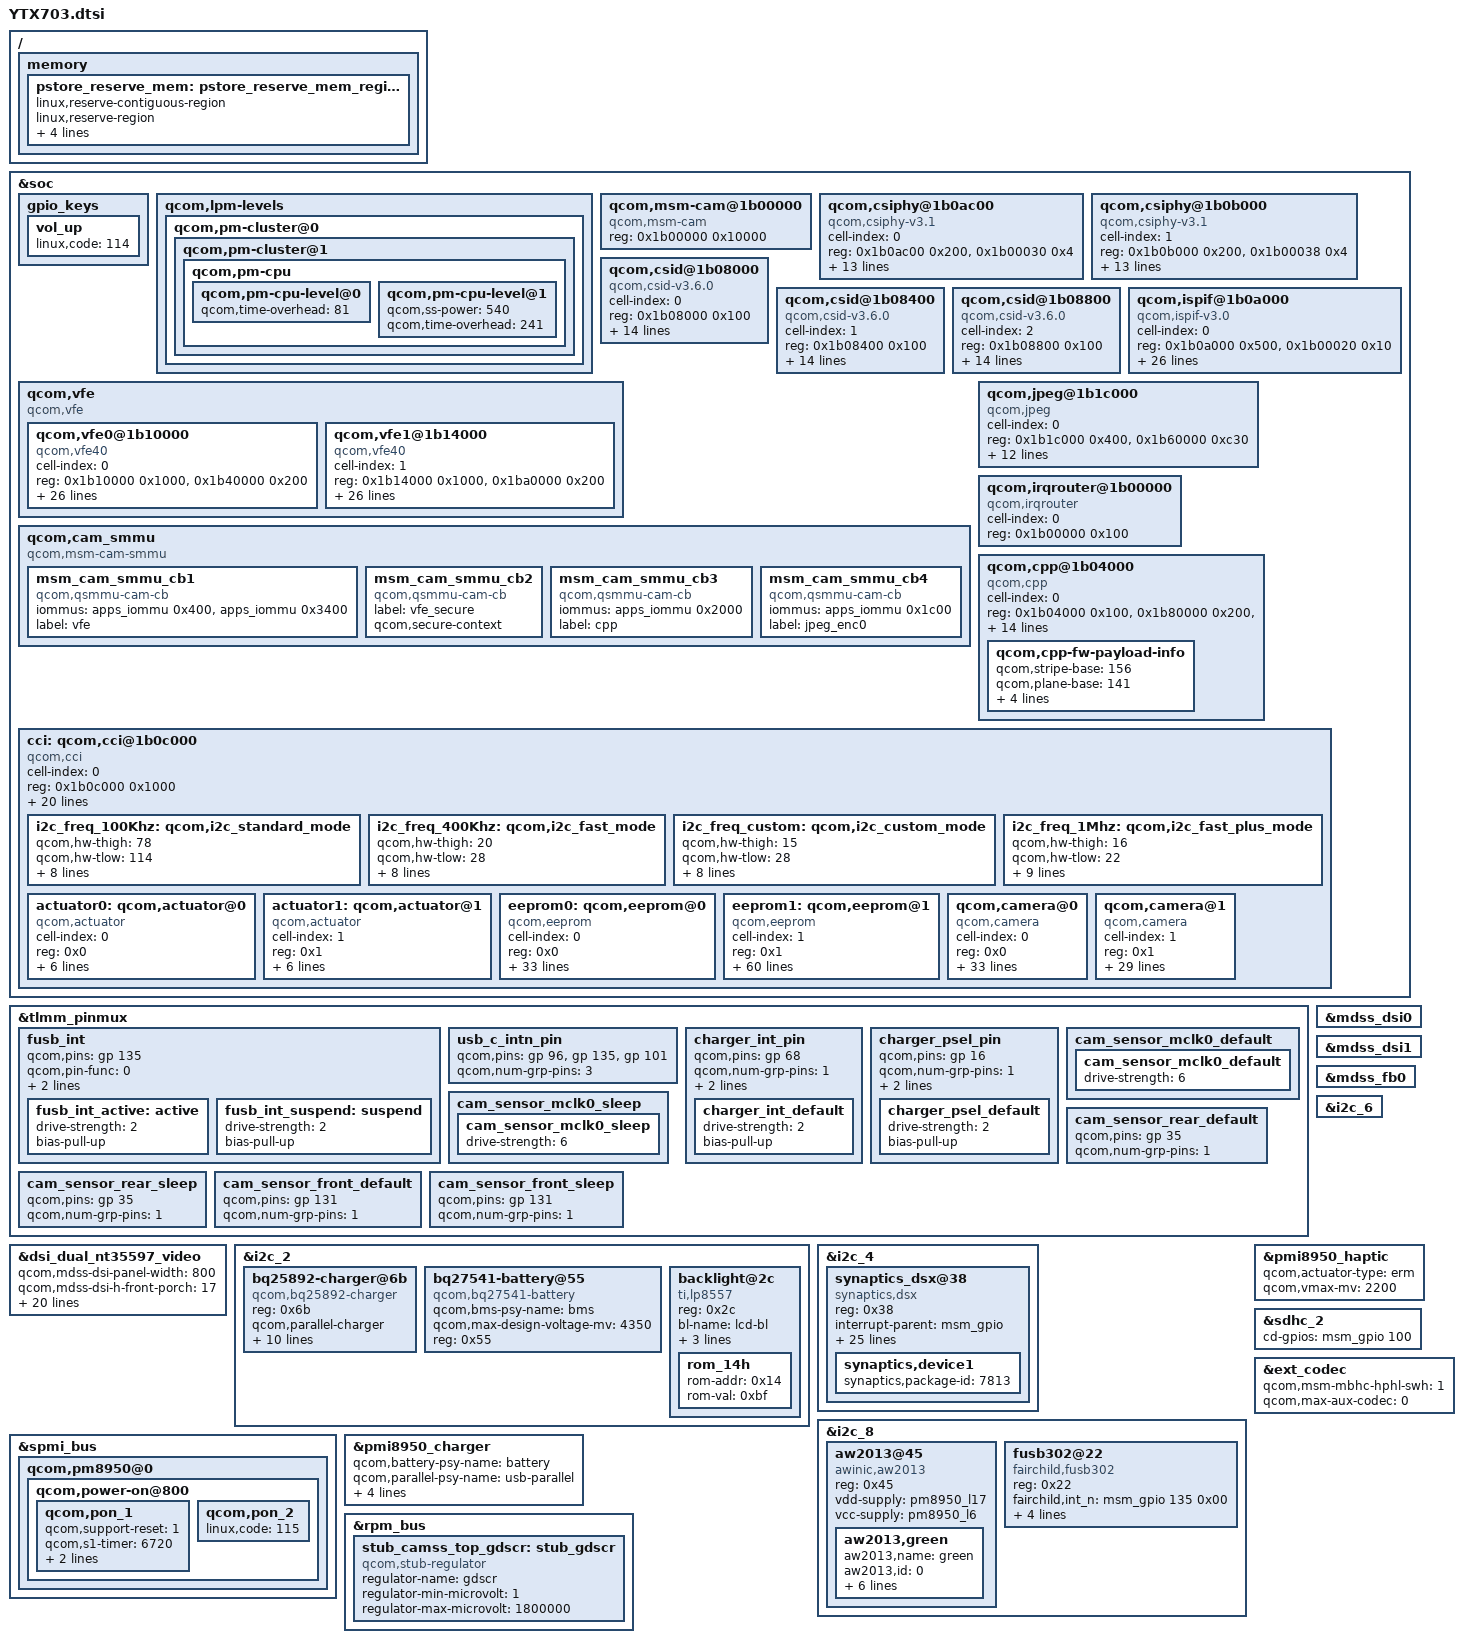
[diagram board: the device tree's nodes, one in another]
/*
 * Copyright (C) 2018 The LineageOS Project
 *
 * This program is free software; you can redistribute it and/or modify
 * it under the terms of the GNU General Public License version 2 and
 * only version 2 as published by the Free Software Foundation.
 *
 * This program is distributed in the hope that it will be useful,
 * but WITHOUT ANY WARRANTY; without even the implied warranty of
 * MERCHANTABILITY or FITNESS FOR A PARTICULAR PURPOSE.  See the
 * GNU General Public License for more details.
 */

/ {
	/* pstore: reserved DDR memory region for post-mortem kernel logs */
	memory {
		pstore_reserve_mem: pstore_reserve_mem_region@0 {
			linux,reserve-contiguous-region;
			linux,reserve-region;
			linux,remove-completely;
			reg = <0x00000000 0x30000000    /* Address */
			       0x00000000 0x00300000>;  /* Size */
			label = "pstore_reserve_mem";
		};
	};
};

&soc {
	/* Compensate for hardware-reversed VOL-UP and VOL-DOWN buttons */
	gpio_keys {
		vol_up {
			linux,code = <114>; /* KEY_VOLUMEDOWN */
		};
	};
	/*
	 * Documentation/devicetree/bindings/arm/msm/lpm-levels.txt
	 * Overrides msm8976-pm.dtsi
	 */
	qcom,lpm-levels {
		qcom,pm-cluster@0 {
			qcom,pm-cluster@1{
				qcom,pm-cpu {
					qcom,pm-cpu-level@0 {
						qcom,time-overhead = <81>;  /* Was 61 */
					};
					qcom,pm-cpu-level@1 {
						qcom,ss-power      = <540>; /* Was 545 */
						qcom,time-overhead = <241>; /* Was 239 */
					};
				};
			};
		};
	};
};

/*
 * Pin muxing settings
 * Overrides msm8976-pinctrl.dtsi
 */
&tlmm_pinmux {
	fusb_int {
		qcom,pins = <&gp 135>;
		qcom,pin-func = <0>;
		qcom,num-grp-pins = <1>;
		label = "fusb_int";
		fusb_int_active: active {
			drive-strength = <2>; /* mA */
			bias-pull-up;
		};
		fusb_int_suspend: suspend {
			drive-strength = <2>; /* mA */
			bias-pull-up;
		};
	};
	usb_c_intn_pin {
		qcom,pins = <&gp 96>, <&gp 135>, <&gp 101>;
		qcom,num-grp-pins = <3>;
	};
	charger_int_pin {
		qcom,pins = <&gp 68>;
		qcom,num-grp-pins = <1>;
		qcom,pin-func = <1>;
		label = "charger_int_pin";
		charger_int_default: charger_int_default {
			drive-strength = <2>; /* mA */
			bias-pull-up;
		};
	};
	charger_psel_pin {
		qcom,pins = <&gp 16>;
		qcom,num-grp-pins = <1>;
		qcom,pin-func = <0>;
		label = "charger_psel_pin";
		charger_psel_default:  charger_psel_default {
			drive-strength = <2>; /* mA */
			bias-pull-up;
		};
	};
	cam_sensor_mclk0_default {
		cam_sensor_mclk0_default {
			drive-strength = <6>; /* mA, previously 2 */
		};
	};
	cam_sensor_mclk0_sleep {
		cam_sensor_mclk0_sleep {
			drive-strength = <6>; /* mA, previously 2 */
		};
	};
	cam_sensor_rear_default {
		qcom,pins = <&gp 35>; /* STANDBY - RESET pin is removed */
		qcom,num-grp-pins = <1>;
	};
	cam_sensor_rear_sleep {
		qcom,pins = <&gp 35>; /* STANDBY - RESET pin is removed */
		qcom,num-grp-pins = <1>;
	};
	cam_sensor_front_default {
		qcom,pins = <&gp 131>; /* RESET - STANDBY pin is removed */
		qcom,num-grp-pins = <1>;
	};
	cam_sensor_front_sleep {
		qcom,pins = <&gp 131>; /* RESET - STANDBY pin is removed */
		qcom,num-grp-pins = <1>;
	};
};

/* LCD panel
 * - Documentation/devicetree/bindings/fb/mdss-dsi-panel.txt
 * - Overrides dsi-panel-nt35597-dualmipi-wqxga-video.dtsi
 */
&dsi_dual_nt35597_video {
	qcom,mdss-dsi-panel-width = <800>;  /* Previously 720 */
	qcom,mdss-dsi-h-front-porch = <17>; /* Horizontal front porch in pixels; previously 100 */
	qcom,mdss-dsi-h-back-porch = <30>;  /* Horizontal back porch in pixels; previously 32 */
	qcom,mdss-dsi-h-pulse-width = <4>;  /* Previously 16 */
	qcom,mdss-dsi-v-back-porch = <24>;  /* Vertical back porch in pixels; previously 7 */
	qcom,mdss-dsi-v-front-porch = <16>; /* Vertical front porch in pixels; previously 8 */
	qcom,mdss-dsi-v-pulse-width = <8>;  /* Previously 1 */
	qcom,mdss-dsi-bl-pmic-control-type = "bl_ctrl_dcs"; /* control backlight via dsi commands */
	/* Backlight controller operates in range 0<x<256 */
	qcom,mdss-dsi-bl-min-level = <0x01>;
	qcom,mdss-dsi-bl-max-level = <0xFF>;
	qcom,mdss-dsi-on-command =
	       [39 01 00 00 01 00 06 f0 55 aa 52 08 00 /* Set internal registers */
	        15 01 00 00 01 00 02 c0 0d
	        39 01 00 00 01 00 05 b8 03 06 00 00
	        39 01 00 00 01 00 05 ff aa 55 a5 80 /* Set internal registers */
	        15 01 00 00 01 00 02 6f 0f
	        15 01 00 00 01 00 02 f7 01
	        39 01 00 00 01 00 05 ff aa 55 a5 00 /* Set internal registers */
	        15 01 00 00 01 00 02 62 01
	        15 01 00 00 01 00 02 51 80 /* Set initial brightness set to 0x80 */
	        05 01 00 00 78 00 02 11 00 /* Exit the sleep mode */
	       ];
	/* DSI PHY timings */
	qcom,mdss-dsi-panel-timings = [D5 32 22 00 60 64 26 34 29 03 04 00];
	qcom,mdss-dsi-post-panel-on-command =
	       [39 01 00 00 01 00 02 FF 23 /* Enter CMD2 page3 */
	        39 01 00 00 00 00 02 00 02 /* DMCT = 1, Select the enable / disable mechanism for CABC and Manual dimming functions. */
	        39 01 00 00 00 00 02 05 24 /* Moving mode dimming 32step, still mode 32step */
	        39 01 00 00 00 00 02 FB 01 /* MTP do not reload CMD2 P3 */
	        39 01 00 00 01 00 02 FF 10 /* Enter CMD1 */
	        15 01 00 00 01 00 02 53 2C /* Enable backlight via pwm control.
	                                      Enable dimming in general (with or w/o cabc). */
	        05 01 00 00 15 00 02 29 00 /* Display on */
	      ];

	/* CABC init commands / values */
	cm,mdss-livedisplay-cabc-cmd = [
	    15 01 00 00 01 00 02 55 00 /* CABC (0: off, 1: UI, 2: Picture, 3: Video) */
	];
	cm,mdss-livedisplay-cabc-ui-value = <0x02>;
	cm,mdss-livedisplay-cabc-image-value = <0x02>;
	cm,mdss-livedisplay-cabc-video-value = <0x02>;
};
/*
 * Overrides msm8976-mdss-mtp.dtsi
 */
&dsi_dual_nt35597_video {
	/delete-property/ qcom,mdss-dsi-pan-enable-dynamic-fps;
	/delete-property/ qcom,mdss-dsi-pan-fps-update;
};
&mdss_dsi0 {
	/delete-property/ qcom,platform-bklight-en-gpio;
};
&mdss_dsi1 {
	/delete-property/ qcom,platform-bklight-en-gpio;
};
/*
 * Disable Linux splash screen at boot
 * Overrides msm8976-mdss.dtsi
 */
&mdss_fb0 {
	/delete-property/ qcom,mdss-fb-splash-logo-enabled;
};

/*
 * Bindings for I2C peripherals
 * Overrides msm8976-mtp.dtsi
 */
&i2c_2 {
	/delete-node/ smb1351-charger@1d;
	bq25892-charger@6b {
		compatible = "qcom,bq25892-charger";
		reg = <0x6b>;
		qcom,parallel-charger;
		qcom,parallel-psy-name = "usb-parallel";
		qcom,float-voltage-mv = <4352>;
		qcom,recharge-mv = <200>;
		qcom,fastchg-current-max-ma = <3800>;
		qcom,iterm-ma = <192>;
		interrupt-parent = <&msm_gpio>;
		interrupts = <68 0>;
		pinctrl-names = "default";
		pinctrl-0 = <&charger_int_default &charger_psel_default>;
		qcom,psel-gpio = <&msm_gpio 16 0>;
	};
	bq27541-battery@55 {
		compatible = "qcom,bq27541-battery";
		qcom,bms-psy-name = "bms";
		qcom,max-design-voltage-mv = <4350>;
		reg = <0x55>;
	};
	backlight@2c {
		compatible = "ti,lp8557";
		reg = <0x2c>;
		bl-name = "lcd-bl";
		dev-ctrl = /bits/ 8 <0x07>; /* see lp8557 documentation, unshaped PWM × brigthness register mode */
		init-brt = /bits/ 8 <0xFF>; /* 255 as initial brightness value;
					       will be multiplied with the value provided by display pwm */
		/* Full-scale LED current (I_LED):
		 * 0:  5 mA,  1: 10 mA,  2: 13 mA,  3: 15 mA,
		 * 4: 18 mA,  5: 20 mA,  6: 23 mA,  7: 25 mA
		 */
		maxcurr-led = <7>;
		/* 4V OV, 4 output LED string enabled */
		rom_14h {
			rom-addr = /bits/ 8 <0x14>;
			rom-val = /bits/ 8 <0xbf>;
		};
	};
};
&i2c_4 {
	/delete-node/ synaptics@20;
	synaptics_dsx@38 {
		compatible = "synaptics,dsx";
		reg = <0x38>;
		interrupt-parent = <&msm_gpio>;
		interrupts = <65 0x2008>;
		avdd-supply = <&pm8950_l17>;
		vdd-supply = <&pm8950_l6>;
		synaptics,pwr-reg-name = "vdd_ana";
		synaptics,bus-reg-name = "vcc_i2c";
		clock-names = "iface_clk", "core_clk";
		clocks = <&clock_gcc clk_gcc_blsp1_ahb_clk>,
			<&clock_gcc clk_gcc_blsp1_qup4_i2c_apps_clk>;
		/* pins used by touchscreen */
		pinctrl-names = "pmx_ts_active","pmx_ts_suspend","pmx_ts_release";
		pinctrl-0 = <&ts_int_active &ts_reset_active>;
		pinctrl-1 = <&ts_int_suspend &ts_reset_suspend>;
		pinctrl-2 = <&ts_release>;
		synaptics,irq-gpio = <&msm_gpio 65 0x2008>;
		synaptics,reset-gpio = <&msm_gpio 64 0x0>;
		synaptics,i2c-pull-up;
		synaptics,power-down;
		synaptics,disable-gpios;
		synaptics,detect-device;
		synaptics,bypass-packrat-id-check;
		synaptics,power-delay-ms = <60>;
		synaptics,reset-on-state = <0>;
		synaptics,reset-active-ms = <10>;
		synaptics,reset-delay-ms = <60>;
		synaptics,ub-i2c-addr = <0x20>;
		synaptics,irq-flags = <0x2008>; /* IRQF_ONESHOT | IRQF_TRIGGER_LOW */
		synaptics,swap-axes; /* ro.sf.hwrotation=90 */
		synaptics,y-flip;
		synaptics,device1 {
			synaptics,package-id = <7813>;
		};
	};
};
&i2c_6 {
	/delete-node/ nq@2b;
};
&i2c_8 {
	aw2013@45 {
		compatible = "awinic,aw2013";
		reg = <0x45>;
		vdd-supply = <&pm8950_l17>; /* msm8976-regulator.dtsi */
		vcc-supply = <&pm8950_l6>;
		aw2013,green {
			aw2013,name = "green";
			aw2013,id = <0>;
			aw2013,max-brightness = <255>;
			aw2013,max-current = <1>;
			aw2013,rise-time-ms = <2>;
			aw2013,hold-time-ms = <1>;
			aw2013,fall-time-ms = <2>;
			aw2013,off-time-ms  = <1>;
		};
	};
	fusb302@22 {
		compatible = "fairchild,fusb302";
		reg = <0x22>;
		fairchild,int_n = <&msm_gpio 135 0x00>;
		interrupt-parent = <&msm_gpio>;
		interrupts = <135 0>; /* MSM GPIO 102 */
		interrupt-names = "fsc_interrupt_int_n";
		pinctrl-names = "fusb_active", "fusb_suspend";
		pinctrl-0 = <&fusb_int_active>;
		pinctrl-1 = <&fusb_int_suspend>;
	};
};

/* SPMI bus peripherals */
&spmi_bus {
	/*
	 * Overrides msm-pm8950.dtsi
	 */
	qcom,pm8950@0 {
		qcom,power-on@800 {
			/* Power button */
			qcom,pon_1 {
				qcom,support-reset = <1>;
				qcom,s1-timer = <6720>; /* button delay until poweroff */
				qcom,s2-timer = <2000>; /* button delay until reboot */
				qcom,s2-type = <5>;
			};
			/* Compensate for hardware-reversed VOL-UP and VOL-DOWN buttons */
			qcom,pon_2 {
				linux,code = <115>; /* KEY_VOLUMEUP */
			};
		};
	};
};
/*
 * Vibration motor
 * Overrides:
 * - msm-pmi8950.dtsi
 * - msm8976-mtp.dtsi
 */
&pmi8950_haptic {
	qcom,actuator-type = "erm";
	qcom,vmax-mv = <2200>;
};
/*
 * Charger
 * Overrides msm-pmi8950.dtsi
 */
&pmi8950_charger { /* qcom,qpnp-smbcharger */
	qcom,battery-psy-name   = "battery";      /* smbcharger driver will register this */
	qcom,parallel-psy-name  = "usb-parallel"; /* BQ25892 */
	qcom,bms-psy-name       = "bms";          /* BQ27541 fuel gauge meter */
	qcom,usb-psy-name       = "usb";          /* phy-msm-usb */
	qcom,fastchg-current-ma = <3000>;
	qcom,iterm-disabled;
	/delete-property/ qcom,iterm-ma;
	/delete-property/ qcom,float-voltage-mv;  /* Moved to BQ25892 */
	/delete-property/ qcom,resume-delta-mv;
	/delete-property/ qcom,autoadjust-vfloat;
	/delete-property/ qcom,force-aicl-rerun;
	/delete-property/ qcom,aicl-rerun-period-s;
	/delete-property/ qcom,charging-disabled;
};

/* SDHC controller
 * - Overrides msm8976-mtp.dtsi
 * - Documentation/devicetree/bindings/mmc/sdhci-msm.txt
 */
&sdhc_2 { /* SDC2 SD card slot */
	/* Disable OF_GPIO_ACTIVE_LOW by default.
	 * Setting will be overridden by drivers/mmc/host/sdhci-msm.c
	 * if bootloader sets com_board_ver < 3 in cmdline.
	 */
	cd-gpios = <&msm_gpio 100 0x0>;
};

/*
 * Audio settings
 * - Overrides msm8976.dtsi
 * - Documentation/devicetree/bindings/sound/qcom-audio-dev.txt
 */
&ext_codec {
	qcom,msm-mbhc-hphl-swh = <1>; /* Headset detection switch is normally open */
	qcom,max-aux-codec = <0>; /* Don't use any wsa881x audio codec */
};

/*
 * RPM bus
 * Overrides msm8976-regulator.dtsi
 * Documentation/devicetree/bindings/regulator/stub-regulator.txt
 */
&rpm_bus {
	stub_camss_top_gdscr: stub_gdscr {
		compatible = "qcom,stub-regulator";
		regulator-name = "gdscr";
		regulator-min-microvolt = <1>;
		regulator-max-microvolt = <1800000>;
	};
};

/*
 * Camera configuration
 * - Forward-ported bindings from LA.BR.1.3.4-06610-8976.0
 * - Documentation/devicetree/bindings/media/video/msm-cci.txt
 * - Overrides msm8976-camera.dtsi
 */
&soc {
	/delete-node/ qcom,msm-cam@1b00000;
	qcom,msm-cam@1b00000 {
		compatible = "qcom,msm-cam";
		reg = <0x1b00000 0x10000>;
		reg-names = "msm-cam";
	};

	/delete-node/ qcom,csiphy@1b0ac00;
	qcom,csiphy@1b0ac00 {
		cell-index = <0>;
		compatible = "qcom,csiphy-v3.1", "qcom,csiphy";
		reg = <0x1b0ac00 0x200>,
		      <0x1b00030 0x4>;
		reg-names = "csiphy", "csiphy_clk_mux";
		interrupts = <0 78 0>;
		interrupt-names = "csiphy";
		clocks = <&clock_gcc clk_gcc_camss_top_ahb_clk>,
		         <&clock_gcc clk_gcc_camss_ispif_ahb_clk>,
		         <&clock_gcc clk_csi0phytimer_clk_src>,
		         <&clock_gcc clk_gcc_camss_csi0phytimer_clk>,
		         <&clock_gcc clk_camss_top_ahb_clk_src>,
		         <&clock_gcc clk_csi2_clk_src>,
		         <&clock_gcc clk_gcc_camss_csi0phy_clk>,
		         <&clock_gcc clk_gcc_camss_csi1phy_clk>,
		         <&clock_gcc clk_gcc_camss_csi2phy_clk>,
		         <&clock_gcc clk_gcc_camss_ahb_clk>;
		clock-names = "camss_top_ahb_clk",
		              "ispif_ahb_clk",
		              "csiphy_timer_src_clk",
		              "csiphy_timer_clk",
		              "camss_ahb_src",
		              "csi_clk",
		              "csi0_phy_clk",
		              "csi1_phy_clk",
		              "csi2_phy_clk",
		              "camss_ahb_clk";
		qcom,clock-rates = <0 61540000 200000000 0 0 200000000 0 0 0 0>;
	};

	/delete-node/ qcom,csiphy@1b0b000;
	qcom,csiphy@1b0b000 {
		cell-index = <1>;
		compatible = "qcom,csiphy-v3.1", "qcom,csiphy";
		reg = <0x1b0b000 0x200>,
			<0x1b00038 0x4>;
		reg-names = "csiphy", "csiphy_clk_mux";
		interrupts = <0 79 0>;
		interrupt-names = "csiphy";
		clocks = <&clock_gcc clk_gcc_camss_top_ahb_clk>,
		         <&clock_gcc clk_gcc_camss_ispif_ahb_clk>,
		         <&clock_gcc clk_csi1phytimer_clk_src>,
		         <&clock_gcc clk_gcc_camss_csi1phytimer_clk>,
		         <&clock_gcc clk_camss_top_ahb_clk_src>,
		         <&clock_gcc clk_csi2_clk_src>,
		         <&clock_gcc clk_gcc_camss_csi0phy_clk>,
		         <&clock_gcc clk_gcc_camss_csi1phy_clk>,
		         <&clock_gcc clk_gcc_camss_csi2phy_clk>,
		         <&clock_gcc clk_gcc_camss_ahb_clk>;
		clock-names = "camss_top_ahb_clk",
		              "ispif_ahb_clk",
		              "csiphy_timer_src_clk",
		              "csiphy_timer_clk",
		              "camss_ahb_src",
		              "csi_clk",
		              "csi0_phy_clk",
		              "csi1_phy_clk",
		              "csi2_phy_clk",
		              "camss_ahb_clk";
		qcom,clock-rates = <0 61540000 200000000 0 0 200000000 0 0 0 0>;
	};

	/delete-node/ qcom,csid@1b08000;
	qcom,csid@1b08000  {
		cell-index = <0>;
		compatible = "qcom,csid-v3.6.0", "qcom,csid";
		reg = <0x1b08000 0x100>;
		reg-names = "csid";
		interrupts = <0 51 0>;
		interrupt-names = "csid";
		qcom,csi-vdd-voltage = <1800000>;
		qcom,mipi-csi-vdd-supply = <&pm8950_l6>;
		clocks = <&clock_gcc clk_gcc_camss_top_ahb_clk>,
		         <&clock_gcc clk_gcc_camss_ispif_ahb_clk>,
		         <&clock_gcc clk_gcc_camss_csi0_ahb_clk>,
		         <&clock_gcc clk_csi0_clk_src>,
		         <&clock_gcc clk_gcc_camss_csi0_clk>,
		         <&clock_gcc clk_gcc_camss_csi0pix_clk>,
		         <&clock_gcc clk_gcc_camss_csi0rdi_clk>,
		         <&clock_gcc clk_gcc_camss_ahb_clk>;
		clock-names = "camss_top_ahb_clk",
		              "ispif_ahb_clk",
		              "csi_ahb_clk",
		              "csi_src_clk",
		              "csi_clk",
		              "csi_pix_clk",
		              "csi_rdi_clk",
		              "camss_ahb_clk";
		qcom,clock-rates = <0 61540000 0 200000000 0 0 0 0>;
		qcom,gdscr-vdd-supply = <&stub_camss_top_gdscr>;
	};

	/delete-node/ qcom,csid@1b08400;
	qcom,csid@1b08400 {
		cell-index = <1>;
		compatible = "qcom,csid-v3.6.0", "qcom,csid";
		reg = <0x1b08400 0x100>;
		reg-names = "csid";
		interrupts = <0 52 0>;
		interrupt-names = "csid";
		qcom,csi-vdd-voltage = <1800000>;
		qcom,mipi-csi-vdd-supply = <&pm8950_l6>;
		clocks = <&clock_gcc clk_gcc_camss_top_ahb_clk>,
		         <&clock_gcc clk_gcc_camss_ispif_ahb_clk>,
		         <&clock_gcc clk_gcc_camss_csi1_ahb_clk>,
		         <&clock_gcc clk_csi1_clk_src>,
		         <&clock_gcc clk_gcc_camss_csi1_clk>,
		         <&clock_gcc clk_gcc_camss_csi1pix_clk>,
		         <&clock_gcc clk_gcc_camss_csi1rdi_clk>,
		         <&clock_gcc clk_gcc_camss_ahb_clk>;
		clock-names = "camss_top_ahb_clk",
		              "ispif_ahb_clk",
		              "csi_ahb_clk",
		              "csi_src_clk",
		              "csi_clk",
		              "csi_pix_clk",
		              "csi_rdi_clk",
		              "camss_ahb_clk";
		qcom,clock-rates = <0 61540000 0 200000000 0 0 0 0>;
		qcom,gdscr-vdd-supply = <&stub_camss_top_gdscr>;
	};

	/delete-node/ qcom,csid@1b08800;
	qcom,csid@1b08800 {
		cell-index = <2>;
		compatible = "qcom,csid-v3.6.0", "qcom,csid";
		reg = <0x1b08800 0x100>;
		reg-names = "csid";
		interrupts = <0 153 0>;
		interrupt-names = "csid";
		qcom,csi-vdd-voltage = <1800000>;
		qcom,mipi-csi-vdd-supply = <&pm8950_l6>;
		clocks = <&clock_gcc clk_gcc_camss_top_ahb_clk>,
		         <&clock_gcc clk_gcc_camss_ispif_ahb_clk>,
		         <&clock_gcc clk_gcc_camss_csi2_ahb_clk>,
		         <&clock_gcc clk_csi2_clk_src>,
		         <&clock_gcc clk_gcc_camss_csi2_clk>,
		         <&clock_gcc clk_gcc_camss_csi2pix_clk>,
		         <&clock_gcc clk_gcc_camss_csi2rdi_clk>,
		         <&clock_gcc clk_gcc_camss_ahb_clk>;
		clock-names = "camss_top_ahb_clk",
		              "ispif_ahb_clk",
		              "csi_ahb_clk",
		              "csi_src_clk",
		              "csi_clk",
		              "csi_pix_clk",
		              "csi_rdi_clk",
		              "camss_ahb_clk";
		qcom,clock-rates = <0 61540000 0 200000000 0 0 0 0>;
		qcom,gdscr-vdd-supply = <&stub_camss_top_gdscr>;
	};

	/delete-node/ qcom,ispif@1b0a000;
	qcom,ispif@1b0a000 {
		cell-index = <0>;
		compatible = "qcom,ispif-v3.0", "qcom,ispif";
		reg = <0x1b0a000 0x500>,
		      <0x1b00020 0x10>;
		reg-names = "ispif", "csi_clk_mux";
		interrupts = <0 55 0>;
		interrupt-names = "ispif";
		qcom,num-isps = <0x2>;
		vfe0-vdd-supply = <&gdsc_vfe>;
		vfe1-vdd-supply = <&gdsc_vfe1>;
		clocks = <&clock_gcc clk_gcc_camss_ispif_ahb_clk>,
		         <&clock_gcc clk_csi0_clk_src>,
		         <&clock_gcc clk_gcc_camss_csi0_clk>,
		         <&clock_gcc clk_gcc_camss_csi0rdi_clk>,
		         <&clock_gcc clk_gcc_camss_csi0pix_clk>,
		         <&clock_gcc clk_csi1_clk_src>,
		         <&clock_gcc clk_gcc_camss_csi1_clk>,
		         <&clock_gcc clk_gcc_camss_csi1rdi_clk>,
		         <&clock_gcc clk_gcc_camss_csi1pix_clk>,
		         <&clock_gcc clk_csi2_clk_src>,
		         <&clock_gcc clk_gcc_camss_csi2_clk>,
		         <&clock_gcc clk_gcc_camss_csi2rdi_clk>,
		         <&clock_gcc clk_gcc_camss_csi2pix_clk>,
		         <&clock_gcc clk_vfe0_clk_src>,
		         <&clock_gcc clk_gcc_camss_vfe0_clk>,
		         <&clock_gcc clk_gcc_camss_csi_vfe0_clk>,
		         <&clock_gcc clk_vfe1_clk_src>,
		         <&clock_gcc clk_gcc_camss_vfe1_clk>,
		         <&clock_gcc clk_gcc_camss_csi_vfe1_clk>;
		clock-names = "ispif_ahb_clk",
		              "csi0_src_clk", "csi0_clk",
		              "csi0_rdi_clk", "csi0_pix_clk",
		              "csi1_src_clk", "csi1_clk",
		              "csi1_rdi_clk", "csi1_pix_clk",
		              "csi2_src_clk", "csi2_clk",
		              "csi2_rdi_clk", "csi2_pix_clk",
		              "vfe0_clk_src", "camss_vfe_vfe0_clk", "camss_csi_vfe0_clk",
		              "vfe1_clk_src", "camss_vfe_vfe1_clk", "camss_csi_vfe1_clk";
		qcom,clock-rates = "61540000",
		                   "200000000", "0", "0", "0",
		                   "200000000", "0", "0", "0",
		                   "200000000", "0", "0", "0",
		                   "0", "0", "0",
		                   "0", "0", "0";
	};

	/delete-node/ qcom,vfe;
	/delete-node/ qcom,vfe0@1b10000;
	/delete-node/ qcom,vfe1@1b14000;
	qcom,vfe {
		compatible = "qcom,vfe";
		#address-cells = <1>;
		#size-cells = <1>;
		ranges;

		qcom,vfe0@1b10000 {
			cell-index = <0>;
			compatible = "qcom,vfe40";
			reg = <0x1b10000 0x1000>,
			      <0x1b40000 0x200>;
			reg-names = "vfe", "vfe_vbif";
			interrupts = <0 57 0>;
			interrupt-names = "vfe";
			vdd-supply = <&gdsc_vfe>;
			clocks = <&clock_gcc clk_gcc_camss_top_ahb_clk>,
			         <&clock_gcc clk_gcc_camss_ahb_clk>,
			         <&clock_gcc clk_vfe0_clk_src>,
			         <&clock_gcc clk_gcc_camss_vfe0_clk>,
			         <&clock_gcc clk_gcc_camss_csi_vfe0_clk>,
			         <&clock_gcc clk_gcc_camss_vfe_ahb_clk>,
			         <&clock_gcc clk_gcc_camss_vfe_axi_clk>,
			         <&clock_gcc clk_gcc_camss_ispif_ahb_clk>;
			clock-names = "camss_top_ahb_clk" , "camss_ahb_clk",
			              "vfe_clk_src", "camss_vfe_vfe_clk",
			              "camss_csi_vfe_clk", "iface_clk",
			              "bus_clk", "iface_ahb_clk";
			qcom,clock-rates = <0 0 266670000 0 0 0 0 0>;
			qos-entries = <8>;
			qos-regs = <0x2C4 0x2C8 0x2CC 0x2D0 0x2D4 0x2D8 0x2DC 0x2E0>;
			qos-settings = <0xaaa9aaa9
			                0xaaa9aaa9 0xaaa9aaa9
			                0xaaa9aaa9 0xaaa9aaa9
			                0xaaa9aaa9 0xaaa9aaa9
			                0xaaa9aaa9>;
			vbif-entries = <1>;
			vbif-regs = <0x124>;
			vbif-settings = <0x3>;
			ds-entries = <17>;
			ds-regs = <0x988 0x98C 0x990 0x994 0x998
			           0x99C 0x9A0 0x9A4 0x9A8 0x9AC 0x9B0
			           0x9B4 0x9B8 0x9BC 0x9C0 0x9C4 0x9C8>;
			ds-settings = <0xcccc0011
			               0xcccc0011 0xcccc0011
			               0xcccc0011 0xcccc0011
			               0xcccc0011 0xcccc0011
			               0xcccc0011 0xcccc0011
			               0xcccc0011 0xcccc0011
			               0xcccc0011 0xcccc0011
			               0xcccc0011 0xcccc0011
			               0xcccc0011 0x00000110>;
			max-clk-nominal = <320000000>;
			max-clk-turbo = <466000000>;
		};

		qcom,vfe1@1b14000 {
			cell-index = <1>;
			compatible = "qcom,vfe40";
			reg = <0x1b14000 0x1000>,
			       <0x1ba0000 0x200>;
			reg-names = "vfe", "vfe_vbif";
			interrupts = <0 29 0>;
			interrupt-names = "vfe";
			vdd-supply = <&gdsc_vfe1>;
			clocks = <&clock_gcc clk_gcc_camss_top_ahb_clk>,
			         <&clock_gcc clk_gcc_camss_ahb_clk>,
			         <&clock_gcc clk_vfe1_clk_src>,
			         <&clock_gcc clk_gcc_camss_vfe1_clk>,
			         <&clock_gcc clk_gcc_camss_csi_vfe1_clk>,
			         <&clock_gcc clk_gcc_camss_vfe1_ahb_clk>,
			         <&clock_gcc clk_gcc_camss_vfe1_axi_clk>,
			         <&clock_gcc clk_gcc_camss_ispif_ahb_clk>;
			clock-names = "camss_top_ahb_clk",
			              "camss_ahb_clk",
			              "vfe_clk_src",
			              "camss_vfe_vfe_clk",
			              "camss_csi_vfe_clk",
			              "iface_clk",
			              "bus_clk",
			              "iface_ahb_clk";
			qcom,clock-rates = <0 0 266670000 0 0 0 0 0>;
			qos-entries = <8>;
			qos-regs = <0x2C4 0x2C8 0x2CC 0x2D0 0x2D4 0x2D8
			            0x2DC 0x2E0>;
			qos-settings = <0xaaa9aaa9
			                0xaaa9aaa9 0xaaa9aaa9
			                0xaaa9aaa9 0xaaa9aaa9
			                0xaaa9aaa9 0xaaa9aaa9
			                0xaaa9aaa9>;
			vbif-entries = <1>;
			vbif-regs = <0x124>;
			vbif-settings = <0x3>;
			ds-entries = <17>;
			ds-regs = <0x988 0x98C 0x990 0x994 0x998
			           0x99C 0x9A0 0x9A4 0x9A8 0x9AC 0x9B0
			           0x9B4 0x9B8 0x9BC 0x9C0 0x9C4 0x9C8>;
			ds-settings = <0xcccc0011
			               0xcccc0011 0xcccc0011
			               0xcccc0011 0xcccc0011
			               0xcccc0011 0xcccc0011
			               0xcccc0011 0xcccc0011
			               0xcccc0011 0xcccc0011
			               0xcccc0011 0xcccc0011
			               0xcccc0011 0xcccc0011
			               0xcccc0011 0x00000110>;
			max-clk-nominal = <320000000>;
			max-clk-turbo = <466000000>;
		};
	};

	/delete-node/ qcom,cam_smmu;
	qcom,cam_smmu {
		compatible = "qcom,msm-cam-smmu";
		msm_cam_smmu_cb1: msm_cam_smmu_cb1 {
			compatible = "qcom,qsmmu-cam-cb";
			iommus = <&apps_iommu 0x400>,
			         <&apps_iommu 0x3400>;
			label = "vfe";
		};

		msm_cam_smmu_cb2: msm_cam_smmu_cb2 {
			compatible = "qcom,qsmmu-cam-cb";
			label = "vfe_secure";
			qcom,secure-context;
		};

		msm_cam_smmu_cb3: msm_cam_smmu_cb3 {
			compatible = "qcom,qsmmu-cam-cb";
			iommus = <&apps_iommu 0x2000>;
			label = "cpp";
		};

		msm_cam_smmu_cb4: msm_cam_smmu_cb4 {
			compatible = "qcom,qsmmu-cam-cb";
			iommus = <&apps_iommu 0x1c00>;
			label = "jpeg_enc0";
		};
	};

	/delete-node/ qcom,jpeg@1b1c000;
	qcom,jpeg@1b1c000 {
		cell-index = <0>;
		compatible = "qcom,jpeg";
		reg = <0x1b1c000 0x400>,
		      <0x1b60000 0xc30>;
		reg-names = "jpeg";
		interrupts = <0 59 0>;
		interrupt-names = "jpeg";
		vdd-supply = <&gdsc_jpeg>;
		clock-names = "core_clk", "iface_clk", "bus_clk0",
		              "camss_top_ahb_clk", "camss_ahb_clk";
		clocks = <&clock_gcc clk_gcc_camss_jpeg0_clk>,
		         <&clock_gcc clk_gcc_camss_jpeg_ahb_clk>,
		         <&clock_gcc clk_gcc_camss_jpeg_axi_clk>,
		         <&clock_gcc clk_gcc_camss_top_ahb_clk>,
		         <&clock_gcc clk_gcc_camss_ahb_clk>;
		qcom,clock-rates = <266670000 0 0 0 0>;
		qos-reg-settings = <0x28 0x0000000e>,
		                   <0xc8 0x00000000>;
		vbif-reg-settings = <0xc0 0x10101000>,
		                    <0xb0 0x10100010>;
	};

	/delete-node/ qcom,irqrouter@1b00000;
	qcom,irqrouter@1b00000 {
		cell-index = <0>;
		compatible = "qcom,irqrouter";
		reg = <0x1b00000 0x100>;
		reg-names = "irqrouter";
	};

	/delete-node/ qcom,cpp@1b04000;
	qcom,cpp@1b04000 {
		cell-index = <0>;
		compatible = "qcom,cpp";
		reg = <0x1b04000 0x100>,
		      <0x1b80000 0x200>,
		      <0x1b18000 0x018>;
		reg-names = "cpp", "cpp_vbif", "cpp_hw";
		interrupts = <0 49 0>;
		interrupt-names = "cpp";
		vdd-supply = <&gdsc_cpp>;
		clocks = <&clock_gcc clk_gcc_camss_top_ahb_clk>,
		         <&clock_gcc clk_cpp_clk_src>,
		         <&clock_gcc clk_gcc_camss_cpp_ahb_clk>,
		         <&clock_gcc clk_gcc_camss_cpp_axi_clk>,
		         <&clock_gcc clk_gcc_camss_cpp_clk>,
		         <&clock_gcc clk_gcc_camss_micro_ahb_clk>,
		         <&clock_gcc clk_gcc_camss_ahb_clk>;
		clock-names = "camss_top_ahb_clk", "cpp_core_clk",
		              "camss_vfe_cpp_ahb_clk", "camss_vfe_cpp_axi_clk",
		              "camss_vfe_cpp_clk","micro_iface_clk", "camss_ahb_clk";
		qcom,clock-rates = <0 240000000 0 0 240000000 0 0>;
		qcom,min-clock-rate = <160000000>;
		bus_master = <1>;
		qcom,cpp-fw-payload-info {
			qcom,stripe-base = <156>;
			qcom,plane-base = <141>;
			qcom,stripe-size = <27>;
			qcom,plane-size = <5>;
			qcom,fe-ptr-off = <5>;
			qcom,we-ptr-off = <11>;
		};
	};

	/delete-node/ qcom,cci@1b0c000;
	cci: qcom,cci@1b0c000 {
		cell-index = <0>;
		compatible = "qcom,cci";
		reg = <0x1b0c000 0x1000>;
		#address-cells = <1>;
		#size-cells = <0>;
		reg-names = "cci";
		interrupts = <0 50 0>;
		interrupt-names = "cci";
		clocks = <&clock_gcc clk_camss_top_ahb_clk_src>,
		         <&clock_gcc clk_gcc_camss_top_ahb_clk>,
		         <&clock_gcc clk_cci_clk_src>,
		         <&clock_gcc clk_gcc_camss_cci_ahb_clk>,
		         <&clock_gcc clk_gcc_camss_cci_clk>,
		         <&clock_gcc clk_gcc_camss_ahb_clk>,
		         <&clock_gcc clk_gcc_camss_ispif_ahb_clk>;
		clock-names = "camss_ahb_src",
		              "camss_top_ahb_clk",
		              "cci_src_clk",
		              "cci_ahb_clk",
		              "camss_cci_clk",
		              "camss_ahb_clk",
		              "ispif_ahb_clk";
		qcom,clock-rates = <40000000 0 19200000 0 0 0 61540000>,
		                   <80000000 0 37500000 0 0 0 61540000>;
		pinctrl-names = "cci_default", "cci_suspend";
		pinctrl-0 = <&cci0_active &cci1_active>;
		pinctrl-1 = <&cci0_suspend &cci1_suspend>;
		gpios = <&msm_gpio 29 0>,
		        <&msm_gpio 30 0>,
		        <&msm_gpio 103 0>,
		        <&msm_gpio 104 0>;
		qcom,gpio-tbl-num = <0 1 2 3>;
		qcom,gpio-tbl-flags = <1 1 1 1>;
		qcom,gpio-tbl-label = "CCI_I2C_DATA0",
		                      "CCI_I2C_CLK0",
		                      "CCI_I2C_DATA1",
		                      "CCI_I2C_CLK1";
		qcom,gdscr-vdd-supply = <&stub_camss_top_gdscr>;
		i2c_freq_100Khz: qcom,i2c_standard_mode {
			 qcom,hw-thigh = <78>;
			 qcom,hw-tlow = <114>;
			 qcom,hw-tsu-sto = <28>;
			 qcom,hw-tsu-sta = <28>;
			 qcom,hw-thd-dat = <10>;
			 qcom,hw-thd-sta = <77>;
			 qcom,hw-tbuf = <118>;
			 qcom,hw-scl-stretch-en = <0>;
			 qcom,hw-trdhld = <6>;
			 qcom,hw-tsp = <1>;
			 status = "ok";
		};
		i2c_freq_400Khz: qcom,i2c_fast_mode {
			qcom,hw-thigh = <20>;
			qcom,hw-tlow = <28>;
			qcom,hw-tsu-sto = <21>;
			qcom,hw-tsu-sta = <21>;
			qcom,hw-thd-dat = <13>;
			qcom,hw-thd-sta = <18>;
			qcom,hw-tbuf = <32>;
			qcom,hw-scl-stretch-en = <0>;
			qcom,hw-trdhld = <6>;
			qcom,hw-tsp = <3>;
		};
		i2c_freq_custom: qcom,i2c_custom_mode {
			qcom,hw-thigh = <15>;
			qcom,hw-tlow = <28>;
			qcom,hw-tsu-sto = <21>;
			qcom,hw-tsu-sta = <21>;
			qcom,hw-thd-dat = <13>;
			qcom,hw-thd-sta = <18>;
			qcom,hw-tbuf = <25>;
			qcom,hw-scl-stretch-en = <1>;
			qcom,hw-trdhld = <6>;
			qcom,hw-tsp = <3>;
		};
		i2c_freq_1Mhz: qcom,i2c_fast_plus_mode {
			qcom,hw-thigh = <16>;
			qcom,hw-tlow = <22>;
			qcom,hw-tsu-sto = <17>;
			qcom,hw-tsu-sta = <18>;
			qcom,hw-thd-dat = <16>;
			qcom,hw-thd-sta = <15>;
			qcom,hw-tbuf = <19>;
			qcom,hw-scl-stretch-en = <1>;
			qcom,hw-trdhld = <3>;
			qcom,hw-tsp = <3>;
			qcom,cci-clk-src = <37500000>;
		};
	};
};

/*
 * - Sensors used in the Lenovo cameras:
 *   * QTech OV5695 (front)
 *   * Sunny DW9761B (back)
 * - Bindings replicate those from msm8976-camera-sensor-mtp.dtsi, but
 *   do not actually override those, since we completely deleted and
 *   redefined the qcom,cci@1b0c000 node right above.
 */
&soc {
	/delete-node/ qcom,camera-flash;
};
&cci {
	actuator0: qcom,actuator@0 {
		cell-index = <0>;
		reg = <0x0>;
		compatible = "qcom,actuator";
		qcom,cci-master = <0>;
		cam_vaf-supply  = <&pm8950_l17>;
		qcom,cam-vreg-name = "cam_vaf";
		qcom,cam-vreg-min-voltage = <2850000>;
		qcom,cam-vreg-max-voltage = <2850000>;
		qcom,cam-vreg-op-mode     = <80000>;
	};
	actuator1: qcom,actuator@1 {
		cell-index = <1>;
		reg = <0x1>;
		compatible = "qcom,actuator";
		qcom,cci-master = <0>;
		cam_vaf-supply  = <&pm8950_l17>;
		qcom,cam-vreg-name = "cam_vaf";
		qcom,cam-vreg-min-voltage = <2850000>;
		qcom,cam-vreg-max-voltage = <2850000>;
		qcom,cam-vreg-op-mode     = <80000>;
	};
	eeprom0: qcom,eeprom@0 {
		cell-index = <0>;
		reg = <0x0>;
		qcom,eeprom-name = "sunny_dw9761b";
		compatible = "qcom,eeprom";
		qcom,slave-addr = <0xb0>;
		qcom,num-blocks = <1>;

		qcom,page0  = <0 0 0 0 0 0>;
		qcom,poll0  = <0 0 0 0 0 0>;
		qcom,saddr0 = <0xb0>;
		qcom,mem0   = <1862 0x0400 2 0 1 0>;

		cam_vaf-supply = <&pm8950_l17>; //AFVDD
		qcom,cam-vreg-name = "cam_vaf";
		qcom,cam-vreg-min-voltage = <2850000>;
		qcom,cam-vreg-max-voltage = <2850000>;
		qcom,cam-vreg-op-mode = <80000>;

		pinctrl-names = "cam_default", "cam_suspend";
		pinctrl-0 = <&cam_sensor_mclk0_default &cam_sensor_rear_default>;
		pinctrl-1 = <&cam_sensor_mclk0_sleep   &cam_sensor_rear_sleep>;
		gpios = <&msm_gpio 26 0>, //MCLK0
		        <&msm_gpio 35 0>; //PWDN
		qcom,gpio-standby = <1>;  //delete gp 38
		qcom,gpio-req-tbl-num   = <0 1>;
		qcom,gpio-req-tbl-flags = <1 0>;
		qcom,gpio-req-tbl-label = "CAMIF_MCLK0", "CAM_STANDBY0";
		qcom,sensor-position = <0>;
		qcom,sensor-mode = <0>;
		qcom,cci-master = <0>;
		qcom,cam-power-seq-type = "sensor_vreg";
		qcom,cam-power-seq-val  = "cam_vaf";
		qcom,cam-power-seq-cfg-val = <1>;
		qcom,cam-power-seq-delay   = <1>;
		qcom,i2c-freq-mode = <1>;
		clocks = <&clock_gcc clk_mclk0_clk_src>,
		         <&clock_gcc clk_gcc_camss_mclk0_clk>;
		clock-names = "cam_src_clk", "cam_clk";
		qcom,clock-rates = <24000000 0>;
	};
	eeprom1: qcom,eeprom@1 {
		cell-index = <1>;
		reg = <0x1>;
		qcom,eeprom-name = "qtech_ov5695";
		compatible = "qcom,eeprom";
		qcom,slave-addr = <0x20>;
		qcom,num-blocks = <8>;

		qcom,page0 = <1 0x0100  2 0x01 1 1>;
		qcom,poll0 = <0 0x0     2 0x0  1 0>;
		qcom,mem0  = <0 0x0     2 0x0  1 0>;
		qcom,page1 = <1 0x5001  2 0x00 1 0>;
		qcom,poll1 = <0 0x0     2 0x0  1 0>;
		qcom,mem1  = <0 0x0     2 0x0  1 0>;
		qcom,page2 = <1 0x3d84  2 0xC0 1 0>;
		qcom,poll2 = <0 0x0     2 0x0  1 0>;
		qcom,mem2  = <0 0x0     2 0x0  1 0>;
		qcom,page3 = <1 0x3d88  2 0x70 1 0>;
		qcom,poll3 = <0 0x0     2 0x0  1 0>;
		qcom,mem3  = <0 0x0     2 0x0  1 0>;
		qcom,page4 = <1 0x3d89  2 0x0c 1 0>;
		qcom,poll4 = <0 0x0     2 0x0  1 0>;
		qcom,mem4  = <0 0x0     2 0x0  1 0>;
		qcom,page5 = <1 0x3d8A  2 0x70 1 0>;
		qcom,poll5 = <0 0x0     2 0x0  1 0>;
		qcom,mem5  = <0 0x0     2 0x0  1 0>;
		qcom,page6 = <1 0x3d8B  2 0x1B 1 0>;
		qcom,poll6 = <0 0x0     2 0x0  1 0>;
		qcom,mem6  = <0 0x0     2 0x0  1 0>;
		qcom,page7 = <1  0x3d81 2 0x01 1 10>;
		qcom,poll7 = <0  0x0    2 0x0  1 1>;
		qcom,mem7  = <16 0x700c 2 0    1 0>;

		cam_vdig-supply = <&pm8950_l23>; //DVDD 1.2V
		cam_vana-supply = <&pm8950_l22>; //AVDD 2.8V
		cam_vio-supply  = <&pm8950_l6>;  //DOVDD  1.8V
		qcom,cam-vreg-name = "cam_vdig", "cam_vio", "cam_vana";
		qcom,cam-vreg-min-voltage = <1200000 0 2800000>;
		qcom,cam-vreg-max-voltage = <1200000 0 2800000>;
		qcom,cam-vreg-op-mode =     <200000  0 80000>;
		pinctrl-names = "cam_default", "cam_suspend";
		pinctrl-0 = <&cam_sensor_mclk2_default &cam_sensor_front_default>;
		pinctrl-1 = <&cam_sensor_mclk2_sleep   &cam_sensor_front_sleep>;
		gpios = <&msm_gpio 28  0>, //MCLK
		        <&msm_gpio 131 0>; //XSHUTDOWN
		qcom,gpio-reset = <1>;
		qcom,gpio-req-tbl-num   = <0 1>;
		qcom,gpio-req-tbl-flags = <1 0>;
		qcom,gpio-req-tbl-label = "CAMIF_MCLK2", "CAM_RESET1";
		qcom,sensor-position = <1>;
		qcom,sensor-mode = <0>;
		qcom,cci-master = <0>;
		qcom,cam-power-seq-type = "sensor_vreg", "sensor_vreg", "sensor_vreg",
		                          "sensor_gpio", "sensor_gpio" , "sensor_clk";
		qcom,cam-power-seq-val  = "cam_vio", "cam_vana", "cam_vdig",
		                          "sensor_gpio_reset", "sensor_gpio_reset","sensor_cam_mclk";
		qcom,cam-power-seq-cfg-val = <1 1 1 0 1 24000000>;
		qcom,cam-power-seq-delay   = <5 5 5 1 5 10>;
		qcom,i2c-freq-mode = <1>;
		clocks = <&clock_gcc clk_mclk2_clk_src>,
		         <&clock_gcc clk_gcc_camss_mclk2_clk>;
		clock-names = "cam_src_clk", "cam_clk";
		qcom,clock-rates = <19200000 0>;
	};
	qcom,camera@0 {
		cell-index = <0>;
		compatible = "qcom,camera";
		reg = <0x0>;
		qcom,csiphy-sd-index = <0>;
		qcom,csid-sd-index   = <0>;
		qcom,mount-angle     = <0>;
		qcom,eeprom-src      = <&eeprom0>;
		qcom,actuator-src    = <&actuator0>;
		cam_vdig-supply      = <&pm8950_l23>; //DVDD 1.2V
		cam_vio-supply       = <&pm8950_l6>;  //IOVDD 1.8V
		cam_vana-supply      = <&pm8950_l22>; //AVDD 2.8V
		cam_vaf-supply       = <&pm8950_l17>; //AFVDD
		qcom,cam-vreg-name = "cam_vdig", "cam_vio", "cam_vana", "cam_vaf";
		qcom,cam-vreg-min-voltage = <1200000 0 2800000 2850000>;
		qcom,cam-vreg-max-voltage = <1200000 0 2800000 2850000>;
		qcom,cam-vreg-op-mode     = <200000  0 80000   100000>;
		qcom,gpio-no-mux = <0>;
		pinctrl-names = "cam_default", "cam_suspend";
		pinctrl-0 = <&cam_sensor_mclk0_default &cam_sensor_rear_default>;
		pinctrl-1 = <&cam_sensor_mclk0_sleep   &cam_sensor_rear_sleep>;
		gpios = <&msm_gpio 26 0>, //MCLK0
		        <&msm_gpio 35 0>; //PWDN
		qcom,gpio-standby = <1>;  //delete gp 38
		qcom,gpio-req-tbl-num   = <0 1>;
		qcom,gpio-req-tbl-flags = <1 0>;
		qcom,gpio-req-tbl-label = "CAMIF_MCLK0", "CAM_STANDBY0";
		qcom,sensor-position = <0>;
		qcom,sensor-mode = <0>;
		qcom,cci-master = <0>;
		clocks = <&clock_gcc clk_mclk0_clk_src>,
		         <&clock_gcc clk_gcc_camss_mclk0_clk>;
		clock-names = "cam_src_clk", "cam_clk";
		qcom,clock-rates = <24000000 0>;
	};
	qcom,camera@1 {
		cell-index = <1>;
		compatible = "qcom,camera";
		reg = <0x1>;
		qcom,csiphy-sd-index = <1>;
		qcom,csid-sd-index   = <1>;
		qcom,mount-angle     = <0>;
		qcom,eeprom-src      = <&eeprom1>;
		cam_vdig-supply      = <&pm8950_l23>; //DVDD  1.2V
		cam_vana-supply      = <&pm8950_l22>; //AVDD  2.8V
		cam_vio-supply       = <&pm8950_l6>;  //DOVDD 1.8V
		qcom,cam-vreg-name = "cam_vdig", "cam_vio", "cam_vana";
		qcom,cam-vreg-min-voltage = <1200000 0 2800000>;
		qcom,cam-vreg-max-voltage = <1200000 0 2800000>;
		qcom,cam-vreg-op-mode     = <200000  0 80000>;
		qcom,gpio-no-mux = <0>;
		pinctrl-names = "cam_default", "cam_suspend";
		pinctrl-0 = <&cam_sensor_mclk2_default &cam_sensor_front_default>;
		pinctrl-1 = <&cam_sensor_mclk2_sleep   &cam_sensor_front_sleep>;
		gpios = <&msm_gpio 28  0>, //MCLK
		        <&msm_gpio 131 0>; //XSHUTDOWN
		qcom,gpio-reset = <1>;
		qcom,gpio-req-tbl-num   = <0 1>;
		qcom,gpio-req-tbl-flags = <1 0>;
		qcom,gpio-req-tbl-label = "CAMIF_MCLK2", "CAM_RESET1";
		qcom,sensor-position = <1>;
		qcom,sensor-mode = <0>;
		qcom,cci-master = <0>;
		clocks = <&clock_gcc clk_mclk2_clk_src>,
		         <&clock_gcc clk_gcc_camss_mclk2_clk>;
		clock-names      = "cam_src_clk", "cam_clk";
		qcom,clock-rates = <24000000 0>;
	};
};

